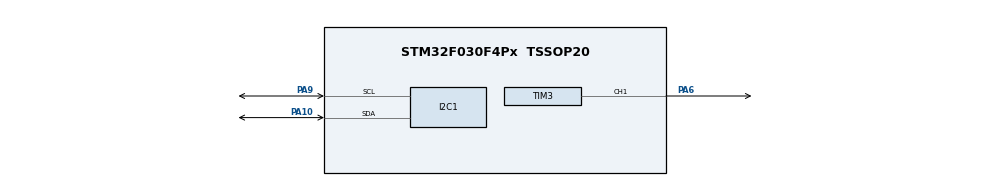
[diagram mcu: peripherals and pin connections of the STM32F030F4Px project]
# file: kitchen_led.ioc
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Mcu.Family=STM32F0
Mcu.Name=STM32F030F4Px
Mcu.Package=TSSOP20
NVIC.TIM1_BRK_UP_TRG_COM_IRQn=true\:0\:0\:false\:false\:true\:true\:true\:true
PA10.Mode=I2C
PA10.Signal=I2C1_SDA
PA13.Mode=Serial_Wire
PA13.Signal=SYS_SWDIO
PA14.Mode=Serial_Wire
PA14.Signal=SYS_SWCLK
PA6.GPIO_Speed=GPIO_SPEED_FREQ_MEDIUM
PA6.Signal=S_TIM3_CH1
PA9.Mode=I2C
PA9.Signal=I2C1_SCL
PF0-OSC_IN.Mode=HSE-External-Oscillator
PF0-OSC_IN.Signal=RCC_OSC_IN
PF1-OSC_OUT.Mode=HSE-External-Oscillator
PF1-OSC_OUT.Signal=RCC_OSC_OUT
ProjectManager.HeapSize=0x200
ProjectManager.StackSize=0x400
ProjectManager.TargetToolchain=STM32CubeIDE
RCC.AHBFreq_Value=8000000
RCC.APB1Freq_Value=8000000
RCC.APB1TimFreq_Value=8000000
RCC.HCLKFreq_Value=8000000
RCC.HSE_VALUE=24000000
RCC.PLLDivider=RCC_PREDIV_DIV8
RCC.PLLMUL=RCC_PLL_MUL6
RCC.PLLSourceVirtual=RCC_PLLSOURCE_HSE
RCC.SYSCLKFreq_VALUE=8000000
SH.S_TIM3_CH1.0=TIM3_CH1,PWM Generation1 CH1
TIM1.Channel-Output\ Compare1\ No\ Output=TIM_CHANNEL_1
TIM1.Period=10000
TIM1.Prescaler=8000
TIM1.TIM_MasterOutputTrigger=TIM_TRGO_OC1REF
TIM3.Channel-PWM\ Generation1\ CH1=TIM_CHANNEL_1
TIM3.OCFastMode_PWM-PWM\ Generation1\ CH1=TIM_OCFAST_ENABLE
TIM3.Period=999
TIM3.Prescaler=180
TIM3.Pulse-PWM\ Generation1\ CH1=100
VP_TIM1_VS_ClockSourceINT.Mode=Internal
VP_TIM1_VS_no_output1.Mode=Output Compare1 No Output
VP_TIM3_VS_ClockSourceINT.Mode=Internal
board=custom

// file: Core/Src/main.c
/* USER CODE BEGIN Header */
/**
  ******************************************************************************
  * @file           : main.c
  * @brief          : Main program body
  ******************************************************************************
  * @attention
  *
  * Copyright (c) 2024 STMicroelectronics.
  * All rights reserved.
  *
  * This software is licensed under terms that can be found in the LICENSE file
  * in the root directory of this software component.
  * If no LICENSE file comes with this software, it is provided AS-IS.
  *
  ******************************************************************************
  */
/* USER CODE END Header */
#include "main.h"

/* USER CODE BEGIN Includes */

#include "vl53l0x_api.h"

/* USER CODE END Includes */

I2C_HandleTypeDef hi2c1;

/* USER CODE BEGIN PV */

VL53L0X_RangingMeasurementData_t RangingData;
VL53L0X_Dev_t  vl53l0x_c; // center module
VL53L0X_DEV    Dev = &vl53l0x_c;

uint16_t ledPwmCycle = 0; //0-999 values

uint8_t ledStatus = 0;
uint8_t ledDelay = 0;

/* USER CODE END PV */

void SystemClock_Config(void);
static void MX_GPIO_Init(void);
static void MX_I2C1_Init(void);
static void MX_TIM3_Init(void);
static void MX_TIM1_Init(void);
/* USER CODE BEGIN PFP */
void TurnLightOn();
void TurnLightOff();

/* USER CODE END PFP */

int main(void)
{

  /* USER CODE BEGIN 1 */
	uint32_t refSpadCount;
	uint8_t isApertureSpads;
	uint8_t VhvSettings;
	uint8_t PhaseCal;

  /* USER CODE END 1 */

  /* MCU Configuration--------------------------------------------------------*/

  /* Reset of all peripherals, Initializes the Flash interface and the Systick. */
  HAL_Init();

  /* Configure the system clock */
  SystemClock_Config();

  /* Initialize all configured peripherals */
  MX_GPIO_Init();
  MX_I2C1_Init();
  MX_TIM3_Init();
  MX_TIM1_Init();
  /* USER CODE BEGIN 2 */

  LL_TIM_EnableCounter(TIM3);
  LL_TIM_CC_EnableChannel(TIM3, LL_TIM_CHANNEL_CH1);

  LL_TIM_EnableIT_UPDATE(TIM1);

  LL_TIM_OC_SetCompareCH1(TIM3, 500);

  Dev->I2cHandle = &hi2c1;
  Dev->I2cDevAddr = 0x52;

  VL53L0X_WaitDeviceBooted(Dev);
  VL53L0X_DataInit(Dev);
  VL53L0X_StaticInit(Dev);

  VL53L0X_PerformRefCalibration(Dev, &VhvSettings, &PhaseCal);
  VL53L0X_PerformRefSpadManagement(Dev, &refSpadCount, &isApertureSpads);
  VL53L0X_SetDeviceMode(Dev, VL53L0X_DEVICEMODE_SINGLE_RANGING);

  //LL_TIM_OC_SetCompareCH1(TIM3, 999);

  /* USER CODE END 2 */

  /* Infinite loop */
  while (1)
  {

    /* USER CODE BEGIN 3 */

	  VL53L0X_PerformSingleRangingMeasurement(Dev, &RangingData);
	  /*
	  if((RangingData.RangeMilliMeter < 300)&&!ledStatus)
	  {
		  TurnLightOn();
	  } else if (ledStatus)
	  {
		  TurnLightOff();
	  }
	  */

	  if((RangingData.RangeMilliMeter < 500))
	  {
		  if(ledStatus == 0)
		  {
			  TurnLightOn();
			  ledDelay = 1;
		  }

		  TIM1->CNT = 0;

	  } else
	  {
		  if(ledStatus == 1)
		  {
			  if (ledDelay == 1)
				  LL_TIM_EnableCounter(TIM1);
			  else
				  TurnLightOff();
		  }
	  }

	  HAL_Delay(100);
  }
  /* USER CODE END 3 */
}

void SystemClock_Config(void)
{
  LL_FLASH_SetLatency(LL_FLASH_LATENCY_0);
  while(LL_FLASH_GetLatency() != LL_FLASH_LATENCY_0)
  {
  }
  LL_RCC_HSI_Enable();

   /* Wait till HSI is ready */
  while(LL_RCC_HSI_IsReady() != 1)
  {

  }
  LL_RCC_HSI_SetCalibTrimming(16);
  LL_RCC_SetAHBPrescaler(LL_RCC_SYSCLK_DIV_1);
  LL_RCC_SetAPB1Prescaler(LL_RCC_APB1_DIV_1);
  LL_RCC_SetSysClkSource(LL_RCC_SYS_CLKSOURCE_HSI);

   /* Wait till System clock is ready */
  while(LL_RCC_GetSysClkSource() != LL_RCC_SYS_CLKSOURCE_STATUS_HSI)
  {

  }
  LL_SetSystemCoreClock(8000000);

   /* Update the time base */
  if (HAL_InitTick (TICK_INT_PRIORITY) != HAL_OK)
  {
    Error_Handler();
  }
  LL_RCC_SetI2CClockSource(LL_RCC_I2C1_CLKSOURCE_HSI);
}

static void MX_I2C1_Init(void)
{

  hi2c1.Instance = I2C1;
  hi2c1.Init.Timing = 0x2000090E;
  hi2c1.Init.OwnAddress1 = 0;
  hi2c1.Init.AddressingMode = I2C_ADDRESSINGMODE_7BIT;
  hi2c1.Init.DualAddressMode = I2C_DUALADDRESS_DISABLE;
  hi2c1.Init.OwnAddress2 = 0;
  hi2c1.Init.OwnAddress2Masks = I2C_OA2_NOMASK;
  hi2c1.Init.GeneralCallMode = I2C_GENERALCALL_DISABLE;
  hi2c1.Init.NoStretchMode = I2C_NOSTRETCH_DISABLE;
  if (HAL_I2C_Init(&hi2c1) != HAL_OK)
  {
    Error_Handler();
  }

  /** Configure Analogue filter
  */
  if (HAL_I2CEx_ConfigAnalogFilter(&hi2c1, I2C_ANALOGFILTER_ENABLE) != HAL_OK)
  {
    Error_Handler();
  }

  /** Configure Digital filter
  */
  if (HAL_I2CEx_ConfigDigitalFilter(&hi2c1, 0) != HAL_OK)
  {
    Error_Handler();
  }

}

static void MX_TIM1_Init(void)
{

  LL_TIM_InitTypeDef TIM_InitStruct = {0};
  LL_TIM_OC_InitTypeDef TIM_OC_InitStruct = {0};
  LL_TIM_BDTR_InitTypeDef TIM_BDTRInitStruct = {0};

  /* Peripheral clock enable */
  LL_APB1_GRP2_EnableClock(LL_APB1_GRP2_PERIPH_TIM1);

  /* TIM1 interrupt Init */
  NVIC_SetPriority(TIM1_BRK_UP_TRG_COM_IRQn, 0);
  NVIC_EnableIRQ(TIM1_BRK_UP_TRG_COM_IRQn);

  TIM_InitStruct.Prescaler = 8000;
  TIM_InitStruct.CounterMode = LL_TIM_COUNTERMODE_UP;
  TIM_InitStruct.Autoreload = 10000;
  TIM_InitStruct.ClockDivision = LL_TIM_CLOCKDIVISION_DIV1;
  TIM_InitStruct.RepetitionCounter = 0;
  LL_TIM_Init(TIM1, &TIM_InitStruct);
  LL_TIM_DisableARRPreload(TIM1);
  LL_TIM_SetClockSource(TIM1, LL_TIM_CLOCKSOURCE_INTERNAL);
  TIM_OC_InitStruct.OCMode = LL_TIM_OCMODE_FROZEN;
  TIM_OC_InitStruct.OCState = LL_TIM_OCSTATE_DISABLE;
  TIM_OC_InitStruct.OCNState = LL_TIM_OCSTATE_DISABLE;
  TIM_OC_InitStruct.CompareValue = 0;
  TIM_OC_InitStruct.OCPolarity = LL_TIM_OCPOLARITY_HIGH;
  TIM_OC_InitStruct.OCNPolarity = LL_TIM_OCPOLARITY_HIGH;
  TIM_OC_InitStruct.OCIdleState = LL_TIM_OCIDLESTATE_LOW;
  TIM_OC_InitStruct.OCNIdleState = LL_TIM_OCIDLESTATE_LOW;
  LL_TIM_OC_Init(TIM1, LL_TIM_CHANNEL_CH1, &TIM_OC_InitStruct);
  LL_TIM_OC_DisableFast(TIM1, LL_TIM_CHANNEL_CH1);
  LL_TIM_SetTriggerOutput(TIM1, LL_TIM_TRGO_OC1REF);
  LL_TIM_DisableMasterSlaveMode(TIM1);
  TIM_BDTRInitStruct.OSSRState = LL_TIM_OSSR_DISABLE;
  TIM_BDTRInitStruct.OSSIState = LL_TIM_OSSI_DISABLE;
  TIM_BDTRInitStruct.LockLevel = LL_TIM_LOCKLEVEL_OFF;
  TIM_BDTRInitStruct.DeadTime = 0;
  TIM_BDTRInitStruct.BreakState = LL_TIM_BREAK_DISABLE;
  TIM_BDTRInitStruct.BreakPolarity = LL_TIM_BREAK_POLARITY_HIGH;
  TIM_BDTRInitStruct.AutomaticOutput = LL_TIM_AUTOMATICOUTPUT_DISABLE;
  LL_TIM_BDTR_Init(TIM1, &TIM_BDTRInitStruct);

}

static void MX_TIM3_Init(void)
{

  LL_TIM_InitTypeDef TIM_InitStruct = {0};
  LL_TIM_OC_InitTypeDef TIM_OC_InitStruct = {0};

  LL_GPIO_InitTypeDef GPIO_InitStruct = {0};

  /* Peripheral clock enable */
  LL_APB1_GRP1_EnableClock(LL_APB1_GRP1_PERIPH_TIM3);

  TIM_InitStruct.Prescaler = 180;
  TIM_InitStruct.CounterMode = LL_TIM_COUNTERMODE_UP;
  TIM_InitStruct.Autoreload = 999;
  TIM_InitStruct.ClockDivision = LL_TIM_CLOCKDIVISION_DIV1;
  LL_TIM_Init(TIM3, &TIM_InitStruct);
  LL_TIM_DisableARRPreload(TIM3);
  LL_TIM_SetClockSource(TIM3, LL_TIM_CLOCKSOURCE_INTERNAL);
  LL_TIM_OC_EnablePreload(TIM3, LL_TIM_CHANNEL_CH1);
  TIM_OC_InitStruct.OCMode = LL_TIM_OCMODE_PWM1;
  TIM_OC_InitStruct.OCState = LL_TIM_OCSTATE_DISABLE;
  TIM_OC_InitStruct.OCNState = LL_TIM_OCSTATE_DISABLE;
  TIM_OC_InitStruct.CompareValue = 100;
  TIM_OC_InitStruct.OCPolarity = LL_TIM_OCPOLARITY_HIGH;
  LL_TIM_OC_Init(TIM3, LL_TIM_CHANNEL_CH1, &TIM_OC_InitStruct);
  LL_TIM_OC_EnableFast(TIM3, LL_TIM_CHANNEL_CH1);
  LL_TIM_SetTriggerOutput(TIM3, LL_TIM_TRGO_RESET);
  LL_TIM_DisableMasterSlaveMode(TIM3);
  LL_AHB1_GRP1_EnableClock(LL_AHB1_GRP1_PERIPH_GPIOA);
  /**TIM3 GPIO Configuration
  PA6   ------> TIM3_CH1
  */
  GPIO_InitStruct.Pin = LL_GPIO_PIN_6;
  GPIO_InitStruct.Mode = LL_GPIO_MODE_ALTERNATE;
  GPIO_InitStruct.Speed = LL_GPIO_SPEED_FREQ_MEDIUM;
  GPIO_InitStruct.OutputType = LL_GPIO_OUTPUT_PUSHPULL;
  GPIO_InitStruct.Pull = LL_GPIO_PULL_NO;
  GPIO_InitStruct.Alternate = LL_GPIO_AF_1;
  LL_GPIO_Init(GPIOA, &GPIO_InitStruct);

}

static void MX_GPIO_Init(void)
{

  /* GPIO Ports Clock Enable */
  LL_AHB1_GRP1_EnableClock(LL_AHB1_GRP1_PERIPH_GPIOF);
  LL_AHB1_GRP1_EnableClock(LL_AHB1_GRP1_PERIPH_GPIOA);

}

/* USER CODE BEGIN 4 */

void TurnLightOn()
{
  for(int i=0; i<999; i++)
  {
	 LL_TIM_OC_SetCompareCH1(TIM3, i);
	 HAL_Delay(1);
  }
  ledStatus = 1;
}

void TurnLightOff()
{
  for(int i=999; i>0; i--)
  {
	 LL_TIM_OC_SetCompareCH1(TIM3, i);
	 HAL_Delay(1);
  }
  ledStatus = 0;
}

void TIM1_Callback(void)
{
	if(LL_TIM_IsActiveFlag_UPDATE(TIM1))
	  {
		LL_TIM_ClearFlag_UPDATE(TIM1);
	  }
	ledDelay = 0;
	LL_TIM_DisableCounter(TIM1);

}

/* USER CODE END 4 */

void Error_Handler(void)
{
  __disable_irq();
  while (1)
  {
  }
}
